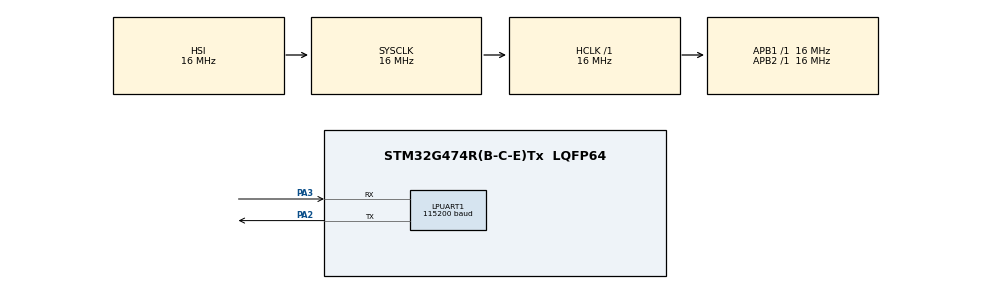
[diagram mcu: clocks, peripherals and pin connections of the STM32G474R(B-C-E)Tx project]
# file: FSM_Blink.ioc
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LPUART1.BaudRate=115200
Mcu.Family=STM32G4
Mcu.Name=STM32G474R(B-C-E)Tx
Mcu.Package=LQFP64
NVIC.LPUART1_IRQn=true\:0\:0\:false\:false\:true\:true\:true\:true
NVIC.PriorityGroup=NVIC_PRIORITYGROUP_4
NVIC.TIM6_DAC_IRQn=true\:0\:0\:false\:false\:true\:true\:true\:true
PA2.Mode=Asynchronous
PA2.Signal=LPUART1_TX
PA3.Mode=Asynchronous
PA3.Signal=LPUART1_RX
ProjectManager.HeapSize=0x200
ProjectManager.StackSize=0x400
ProjectManager.TargetToolchain=STM32CubeIDE
RCC.AHBFreq_Value=16000000
RCC.APB1Freq_Value=16000000
RCC.APB1TimFreq_Value=16000000
RCC.APB2Freq_Value=16000000
RCC.APB2TimFreq_Value=16000000
RCC.CortexFreq_Value=16000000
RCC.EXTERNAL_CLOCK_VALUE=12288000
RCC.HCLKFreq_Value=16000000
RCC.HSE_VALUE=8000000
RCC.HSI48_VALUE=48000000
RCC.HSI_VALUE=16000000
RCC.LSE_VALUE=32768
RCC.SYSCLKFreq_VALUE=16000000
RCC.USBFreq_Value=64000000
RCC.VCOOutputFreq_Value=128000000
TIM6.PeriodNoDither=9
TIM6.Prescaler=1599
VP_SYS_VS_DBSignals.Mode=DisableDeadBatterySignals
VP_TIM6_VS_ClockSourceINT.Mode=Enable_Timer
board=NUCLEO-G474RE

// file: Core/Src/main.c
/* USER CODE BEGIN Header */
/**
  ******************************************************************************
  * @file           : main.c
  * @brief          : Main program body
  ******************************************************************************
  * @attention
  *
  * Copyright (c) 2026 STMicroelectronics.
  * All rights reserved.
  *
  * This software is licensed under terms that can be found in the LICENSE file
  * in the root directory of this software component.
  * If no LICENSE file comes with this software, it is provided AS-IS.
  *
  ******************************************************************************
  */
/* USER CODE END Header */
#include "main.h"

/* USER CODE BEGIN Includes */
#include <stdio.h>
#include <string.h>
/* USER CODE END Includes */

/* USER CODE BEGIN PTD */
typedef enum {
	LED_ON,
	LED_OFF
} LedState_t;

typedef enum {
	SLOW = 1000,
	MID = 500,
	FAST = 100
} PulseSpeed_t;
/* USER CODE END PTD */

/* USER CODE BEGIN PD */
#define CLEAR_SCREEN "\x1b[2J\x1b[H"
#define RX_RING_SIZE 64
#define TX_RING_SIZE 128
/* USER CODE END PD */

UART_HandleTypeDef hlpuart1;

TIM_HandleTypeDef htim6;

/* USER CODE BEGIN PV */
volatile uint8_t buttonPressed = 0;
static uint32_t lastPressAction = 0;

static const uint32_t debounceWindow = 20;
volatile uint32_t ms_counter = 0;

volatile uint8_t rxByte = 0;
uint8_t line_buffer[RX_RING_SIZE] = {0};
uint8_t line_buffer_index = 0;

volatile uint8_t rx_ring[RX_RING_SIZE];
volatile uint16_t rx_head = 0;
volatile uint16_t rx_tail = 0;
volatile uint32_t rx_overruns = 0;

volatile uint8_t tx_ring[TX_RING_SIZE];
volatile uint16_t tx_head = 0;
volatile uint16_t tx_tail = 0;
volatile uint32_t tx_overruns = 0;
volatile uint8_t tx_busy = 0;
/* USER CODE END PV */

void SystemClock_Config(void);
static void MX_GPIO_Init(void);
static void MX_TIM6_Init(void);
static void MX_LPUART1_UART_Init(void);

int main(void)
{

  /* MCU Configuration--------------------------------------------------------*/

  /* Reset of all peripherals, Initializes the Flash interface and the Systick. */
  HAL_Init();

  /* Configure the system clock */
  SystemClock_Config();

  /* USER CODE BEGIN SysInit */
  TIM6_CLK_ENABLE();
  /* USER CODE END SysInit */

  /* Initialize all configured peripherals */
  MX_GPIO_Init();
  MX_TIM6_Init();
  MX_LPUART1_UART_Init();
  /* USER CODE BEGIN 2 */
  HAL_UART_Receive_IT(&hlpuart1, &rxByte, 1);
  GPIO_InitTypeDef GPIO_InitStruct = {0};

  LED_GPIO_CLK_ENABLE();
  GPIO_InitStruct.Pin = LED_PIN;
  GPIO_InitStruct.Mode = GPIO_MODE_OUTPUT_PP;
  GPIO_InitStruct.Pull = GPIO_NOPULL;
  GPIO_InitStruct.Speed = GPIO_SPEED_FREQ_LOW;
  HAL_GPIO_Init(LED_GPIO_PORT, &GPIO_InitStruct);

  BTN_GPIO_CLK_ENABLE();
  GPIO_InitStruct.Pin = BTN_PIN;
  GPIO_InitStruct.Mode = GPIO_MODE_IT_FALLING;
  GPIO_InitStruct.Pull = GPIO_NOPULL;
  HAL_GPIO_Init(BTN_GPIO_PORT, &GPIO_InitStruct);
  HAL_NVIC_SetPriority(BTN_EXTI_IRQn, 0, 0);
  HAL_NVIC_EnableIRQ(BTN_EXTI_IRQn);

  HAL_NVIC_SetPriority(TIM6_DAC_IRQn, 1, 0);
  HAL_NVIC_EnableIRQ(TIM6_DAC_IRQn);
  HAL_TIM_Base_Start_IT(&htim6);

  /* USER CODE END 2 */

  /* Infinite loop */
  /* USER CODE BEGIN WHILE */
  LedState_t led_state = LED_OFF;
  PulseSpeed_t speed = SLOW;
  uint32_t lastTransition = ms_counter;

  while (1)
  {

	  uint32_t now = ms_counter;

	  if (buttonPressed) {
		  buttonPressed = 0;
		  if (now - lastPressAction >= debounceWindow) {
			  lastPressAction = now;
			  lastTransition = now;
			  switch (speed) {
			  case SLOW: speed = MID;  break;
			  case MID:  speed = FAST; break;
			  case FAST: speed = SLOW; break;
			  }
		  }
	  }

	  if (now - lastTransition >= speed) {
		  switch (led_state) {
		  case LED_OFF: led_state = LED_ON;  break;
		  case LED_ON:  led_state = LED_OFF; break;
		  }
		  lastTransition = now;

		  switch(led_state) {
		  case LED_OFF:
			  HAL_GPIO_WritePin(LED_GPIO_PORT, LED_PIN, GPIO_PIN_RESET); break;
		  case LED_ON:
			  HAL_GPIO_WritePin(LED_GPIO_PORT, LED_PIN, GPIO_PIN_SET); break;
		  }
	  }

	  uint8_t c;
	  while (rx_ring_get(&c)) {
		  if (c == '\b' && line_buffer_index > 0) {
			  line_buffer_index--;
			  printf("\b\x20\b");
			  fflush(stdout);
		  } else if (c == '\n' || c == '\r') {
			  line_buffer[line_buffer_index] = '\0';
			  if(strcmp(line_buffer, "fast") == 0) {
				  speed = FAST;
			  } else if (strcmp(line_buffer, "mid") == 0) {
				  speed = MID;
			  } else if (strcmp(line_buffer, "slow") == 0) {
				  speed = SLOW;
			  }
			  line_buffer_index = 0;
			  printf("\r\n");
		  } else if (line_buffer_index < RX_RING_SIZE - 1) {
			  line_buffer[line_buffer_index++] = c;
			  if (c >= 0x20 && c <= 0x7E) {
				  printf("%c", c);
				  fflush(stdout);
			  }
		  }
	  }

    /* USER CODE END WHILE */

  }
}

void SystemClock_Config(void)
{
  RCC_OscInitTypeDef RCC_OscInitStruct = {0};
  RCC_ClkInitTypeDef RCC_ClkInitStruct = {0};

  /** Configure the main internal regulator output voltage
  */
  HAL_PWREx_ControlVoltageScaling(PWR_REGULATOR_VOLTAGE_SCALE1);

  /** Initializes the RCC Oscillators according to the specified parameters
  * in the RCC_OscInitTypeDef structure.
  */
  RCC_OscInitStruct.OscillatorType = RCC_OSCILLATORTYPE_HSI;
  RCC_OscInitStruct.HSIState = RCC_HSI_ON;
  RCC_OscInitStruct.HSICalibrationValue = RCC_HSICALIBRATION_DEFAULT;
  RCC_OscInitStruct.PLL.PLLState = RCC_PLL_NONE;
  if (HAL_RCC_OscConfig(&RCC_OscInitStruct) != HAL_OK)
  {
    Error_Handler();
  }

  /** Initializes the CPU, AHB and APB buses clocks
  */
  RCC_ClkInitStruct.ClockType = RCC_CLOCKTYPE_HCLK|RCC_CLOCKTYPE_SYSCLK
                              |RCC_CLOCKTYPE_PCLK1|RCC_CLOCKTYPE_PCLK2;
  RCC_ClkInitStruct.SYSCLKSource = RCC_SYSCLKSOURCE_HSI;
  RCC_ClkInitStruct.AHBCLKDivider = RCC_SYSCLK_DIV1;
  RCC_ClkInitStruct.APB1CLKDivider = RCC_HCLK_DIV1;
  RCC_ClkInitStruct.APB2CLKDivider = RCC_HCLK_DIV1;

  if (HAL_RCC_ClockConfig(&RCC_ClkInitStruct, FLASH_LATENCY_0) != HAL_OK)
  {
    Error_Handler();
  }
}

static void MX_LPUART1_UART_Init(void)
{

  hlpuart1.Instance = LPUART1;
  hlpuart1.Init.BaudRate = 115200;
  hlpuart1.Init.WordLength = UART_WORDLENGTH_8B;
  hlpuart1.Init.StopBits = UART_STOPBITS_1;
  hlpuart1.Init.Parity = UART_PARITY_NONE;
  hlpuart1.Init.Mode = UART_MODE_TX_RX;
  hlpuart1.Init.HwFlowCtl = UART_HWCONTROL_NONE;
  hlpuart1.Init.OneBitSampling = UART_ONE_BIT_SAMPLE_DISABLE;
  hlpuart1.Init.ClockPrescaler = UART_PRESCALER_DIV1;
  hlpuart1.AdvancedInit.AdvFeatureInit = UART_ADVFEATURE_NO_INIT;
  if (HAL_UART_Init(&hlpuart1) != HAL_OK)
  {
    Error_Handler();
  }
  if (HAL_UARTEx_SetTxFifoThreshold(&hlpuart1, UART_TXFIFO_THRESHOLD_1_8) != HAL_OK)
  {
    Error_Handler();
  }
  if (HAL_UARTEx_SetRxFifoThreshold(&hlpuart1, UART_RXFIFO_THRESHOLD_1_8) != HAL_OK)
  {
    Error_Handler();
  }
  if (HAL_UARTEx_DisableFifoMode(&hlpuart1) != HAL_OK)
  {
    Error_Handler();
  }
  /* USER CODE BEGIN LPUART1_Init 2 */
  printf(CLEAR_SCREEN);
  HAL_Delay(20);
  printf("=== LED FSM v1.0 ===\r\n");
  /* USER CODE END LPUART1_Init 2 */

}

static void MX_TIM6_Init(void)
{

  TIM_MasterConfigTypeDef sMasterConfig = {0};

  htim6.Instance = TIM6;
  htim6.Init.Prescaler = 1599;
  htim6.Init.CounterMode = TIM_COUNTERMODE_UP;
  htim6.Init.Period = 9;
  htim6.Init.AutoReloadPreload = TIM_AUTORELOAD_PRELOAD_DISABLE;
  if (HAL_TIM_Base_Init(&htim6) != HAL_OK)
  {
    Error_Handler();
  }
  sMasterConfig.MasterOutputTrigger = TIM_TRGO_RESET;
  sMasterConfig.MasterSlaveMode = TIM_MASTERSLAVEMODE_DISABLE;
  if (HAL_TIMEx_MasterConfigSynchronization(&htim6, &sMasterConfig) != HAL_OK)
  {
    Error_Handler();
  }

}

static void MX_GPIO_Init(void)
{

  /* GPIO Ports Clock Enable */
  __HAL_RCC_GPIOA_CLK_ENABLE();

}

/* USER CODE BEGIN 4 */
void BTN_EXTI_IRQHandler(void)
{
	HAL_GPIO_EXTI_IRQHandler(BTN_PIN);
}

void HAL_GPIO_EXTI_Callback(uint16_t GPIO_Pin)
{
	if (GPIO_Pin == BTN_PIN) {
		buttonPressed = 1;
	}
}

void HAL_TIM_PeriodElapsedCallback(TIM_HandleTypeDef *htim)
{
	if (htim->Instance == TIM6) {
		ms_counter++;
	}
}

int __io_putchar(int ch)
{
	tx_ring_put(ch);
	return ch;
}

void HAL_UART_RxCpltCallback(UART_HandleTypeDef *huart)
{
	if (huart->Instance == LPUART1) {
		rx_ring_put(rxByte);
		HAL_UART_Receive_IT(&hlpuart1, &rxByte, 1);
	}
}

void rx_ring_put(uint8_t byte)
{
	uint16_t next = (rx_head + 1) & (RX_RING_SIZE - 1);
	if (next == rx_tail) {
		rx_overruns++;
		return;
	}
	rx_ring[rx_head] = byte;
	rx_head = next;
}

int rx_ring_get(uint8_t *out)
{
	if (rx_head == rx_tail) {
		return 0;
	}
	*out = rx_ring[rx_tail];
	rx_tail = (rx_tail + 1) & (RX_RING_SIZE - 1);
	return 1;
}

void HAL_UART_TxCpltCallback(UART_HandleTypeDef *huart)
{
	if (huart->Instance == LPUART1) {
		tx_tail = (tx_tail + 1) & (TX_RING_SIZE - 1);

		if (tx_head != tx_tail) {
			HAL_UART_Transmit_IT(&hlpuart1, (uint8_t *)&tx_ring[tx_tail], 1);
		} else {
			tx_busy = 0;
		}
	}
}

void tx_ring_put(uint8_t byte)
{
	uint32_t primask = __get_PRIMASK();
		__disable_irq();

	uint16_t next = (tx_head + 1) & (TX_RING_SIZE - 1);

	if (next == tx_tail) {
		tx_overruns++;
		__set_PRIMASK(primask);
		return;
	}

	tx_ring[tx_head] = byte;
	tx_head = next;

	if (!tx_busy) {
		tx_busy = 1;
		HAL_UART_Transmit_IT(&hlpuart1, (uint8_t *)&tx_ring[tx_tail], 1);
	}

	__set_PRIMASK(primask);
}
/* USER CODE END 4 */

void Error_Handler(void)
{
  __disable_irq();
  while (1)
  {
  }
}
